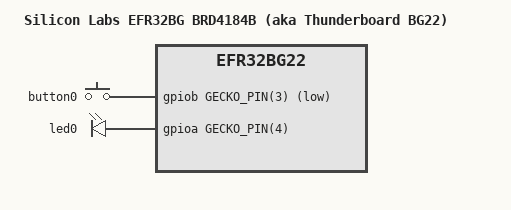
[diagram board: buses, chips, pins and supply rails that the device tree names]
/*
 * Copyright (c) 2021 Sateesh Kotapati
 * Copyright (c) 2023 Piotr Dymacz
 *
 * SPDX-License-Identifier: Apache-2.0
 */

/dts-v1/;
#include <silabs/efr32bg22.dtsi>
#include <silabs/efr32bg2x-pinctrl.dtsi>
#include "efr32bg22_brd4184.dtsi"

/ {
	model = "Silicon Labs EFR32BG BRD4184B (aka Thunderboard BG22)";
	compatible = "silabs,efr32bg22c224f512im40", "silabs,efr32bg_brd4184b",
		"silabs,efr32bg22";
};

&button0 {
	gpios = <&gpiob GECKO_PIN(3) GPIO_ACTIVE_LOW>;
};

&led0 {
	gpios = <&gpioa GECKO_PIN(4) GPIO_ACTIVE_HIGH>;
};

&sw_sensor_enable {
	enable-gpios = <&gpioc GECKO_PIN(6) GPIO_ACTIVE_HIGH>;
};

&sw_mic_enable {
	enable-gpios = <&gpioc GECKO_PIN(7) GPIO_ACTIVE_HIGH>;
};
